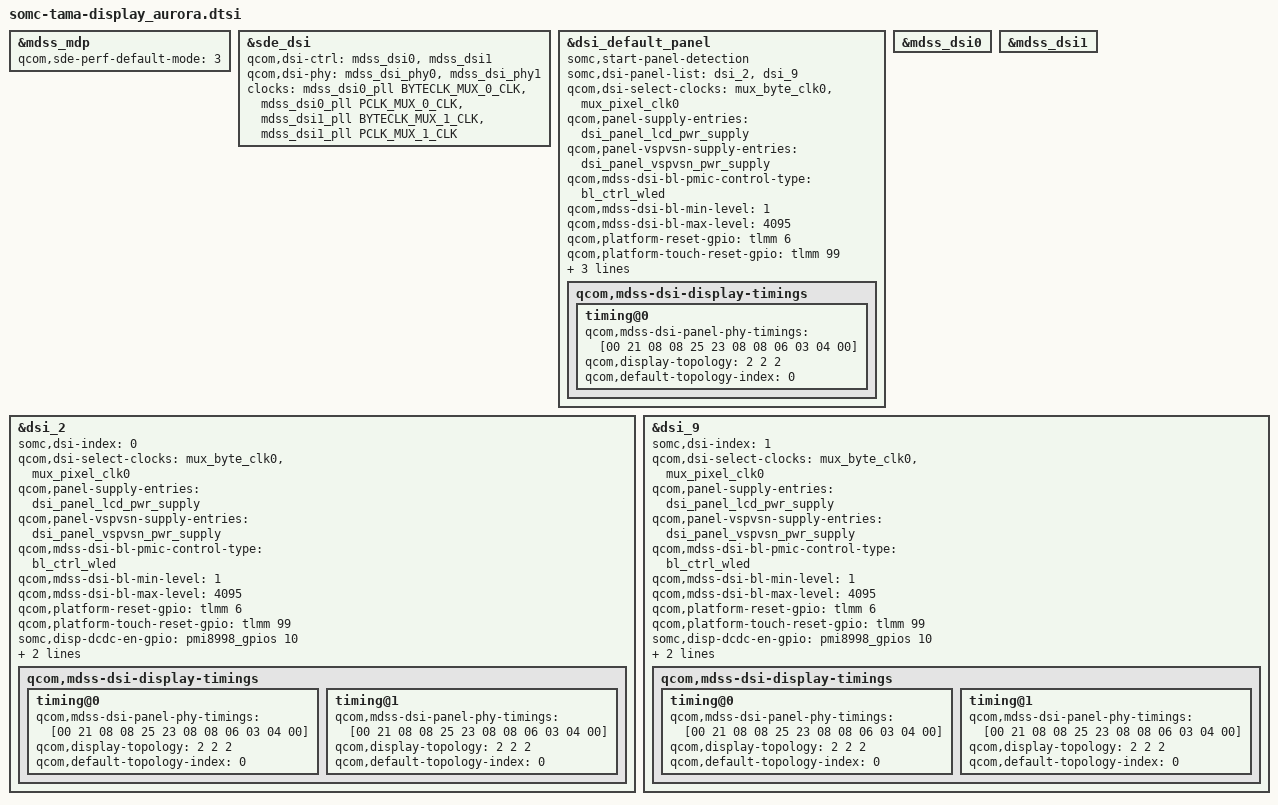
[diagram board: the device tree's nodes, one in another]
// SPDX-License-Identifier: GPL-2.0-only
/*
 * Copyright (c) 2015-2017, The Linux Foundation. All rights reserved.
 */

&mdss_mdp {
	/* Set SDE MAX performance */
	qcom,sde-perf-default-mode = <3>;
};

&sde_dsi {
	qcom,dsi-ctrl = <&mdss_dsi0 &mdss_dsi1>;
	qcom,dsi-phy = <&mdss_dsi_phy0 &mdss_dsi_phy1>;

	clocks = <&mdss_dsi0_pll BYTECLK_MUX_0_CLK>,
		<&mdss_dsi0_pll PCLK_MUX_0_CLK>,
		<&mdss_dsi1_pll BYTECLK_MUX_1_CLK>,
		<&mdss_dsi1_pll PCLK_MUX_1_CLK>;
	clock-names = "mux_byte_clk0", "mux_pixel_clk0",
		"mux_byte_clk1", "mux_pixel_clk1";
};

&dsi_default_panel {
	somc,start-panel-detection;
	somc,dsi-panel-list = <&dsi_2 &dsi_9>;
	qcom,dsi-select-clocks = "mux_byte_clk0", "mux_pixel_clk0";
	/delete-property/ qcom,panel-touch-supply-entries;
	qcom,panel-supply-entries = <&dsi_panel_lcd_pwr_supply>;
	qcom,panel-vspvsn-supply-entries = <&dsi_panel_vspvsn_pwr_supply>;
	qcom,mdss-dsi-bl-pmic-control-type = "bl_ctrl_wled";
	qcom,mdss-dsi-bl-min-level = <1>;
	qcom,mdss-dsi-bl-max-level = <4095>;
	qcom,platform-reset-gpio = <&tlmm 6 0>;
	qcom,platform-touch-reset-gpio = <&tlmm 99 0>;
	somc,disp-dcdc-en-gpio = <&pmi8998_gpios 10 0>;
	qcom,mdss-dsi-t-clk-post = <0x0E>;
	qcom,mdss-dsi-t-clk-pre = <0x33>;
	qcom,mdss-dsi-display-timings {
		timing@0 {
			qcom,mdss-dsi-panel-phy-timings = [00 21 08 08 25 23 08 08 06 03 04 00];
			qcom,display-topology = <2 2 2>;
			qcom,default-topology-index = <0>;
		};
	};
};

&mdss_dsi0 {
	/delete-property/ qcom,null-insertion-enabled;
};

&mdss_dsi1 {
	/delete-property/ qcom,null-insertion-enabled;
};

&dsi_2 {
	somc,dsi-index = <0>;
	qcom,dsi-select-clocks = "mux_byte_clk0", "mux_pixel_clk0";
	qcom,panel-supply-entries = <&dsi_panel_lcd_pwr_supply>;
	qcom,panel-vspvsn-supply-entries = <&dsi_panel_vspvsn_pwr_supply>;
	qcom,mdss-dsi-bl-pmic-control-type = "bl_ctrl_wled";
	qcom,mdss-dsi-bl-min-level = <1>;
	qcom,mdss-dsi-bl-max-level = <4095>;
	qcom,platform-reset-gpio = <&tlmm 6 0>;
	qcom,platform-touch-reset-gpio = <&tlmm 99 0>;
	somc,disp-dcdc-en-gpio = <&pmi8998_gpios 10 0>;
	qcom,mdss-dsi-t-clk-post = <0x0E>;
	qcom,mdss-dsi-t-clk-pre = <0x33>;
	qcom,mdss-dsi-display-timings {
		timing@0 {
			qcom,mdss-dsi-panel-phy-timings = [00 21 08 08 25 23 08 08 06 03 04 00];
			qcom,display-topology = <2 2 2>;
			qcom,default-topology-index = <0>;
		};
		timing@1 {
			qcom,mdss-dsi-panel-phy-timings = [00 21 08 08 25 23 08 08 06 03 04 00];
			qcom,display-topology = <2 2 2>;
			qcom,default-topology-index = <0>;
		};
	};
};

&dsi_9 {
	somc,dsi-index = <1>;
	qcom,dsi-select-clocks = "mux_byte_clk0", "mux_pixel_clk0";
	qcom,panel-supply-entries = <&dsi_panel_lcd_pwr_supply>;
	qcom,panel-vspvsn-supply-entries = <&dsi_panel_vspvsn_pwr_supply>;
	qcom,mdss-dsi-bl-pmic-control-type = "bl_ctrl_wled";
	qcom,mdss-dsi-bl-min-level = <1>;
	qcom,mdss-dsi-bl-max-level = <4095>;
	qcom,platform-reset-gpio = <&tlmm 6 0>;
	qcom,platform-touch-reset-gpio = <&tlmm 99 0>;
	somc,disp-dcdc-en-gpio = <&pmi8998_gpios 10 0>;
	qcom,mdss-dsi-t-clk-post = <0x0E>;
	qcom,mdss-dsi-t-clk-pre = <0x33>;
	qcom,mdss-dsi-display-timings {
		timing@0 {
			qcom,mdss-dsi-panel-phy-timings = [00 21 08 08 25 23 08 08 06 03 04 00];
			qcom,display-topology = <2 2 2>;
			qcom,default-topology-index = <0>;
		};
		timing@1 {
			qcom,mdss-dsi-panel-phy-timings = [00 21 08 08 25 23 08 08 06 03 04 00];
			qcom,display-topology = <2 2 2>;
			qcom,default-topology-index = <0>;
		};
	};
};
